# R40 register map
Vendor: Allwinner; Series: R40; File version: 0.1
CPU: CA7 0, little endian, MPU, FPU, double-precision FPU, 0 interrupt priority bits
Registers are 32-bit, read-write, reset 0x0 unless marked. A register's access mark holds for its fields unless they carry their own. Offsets are from the block's base; [hi:lo] are bit positions; lines under a group give offsets from that group; {n}, {i} and the like mark numbered series.

## Thermal_Sensor
Base 0x01C24C00
0x00 THS_CTRL_REG0
  [15:0] SENSOR_ACQ — Sensor acquire time CLK_IN/(N+1)
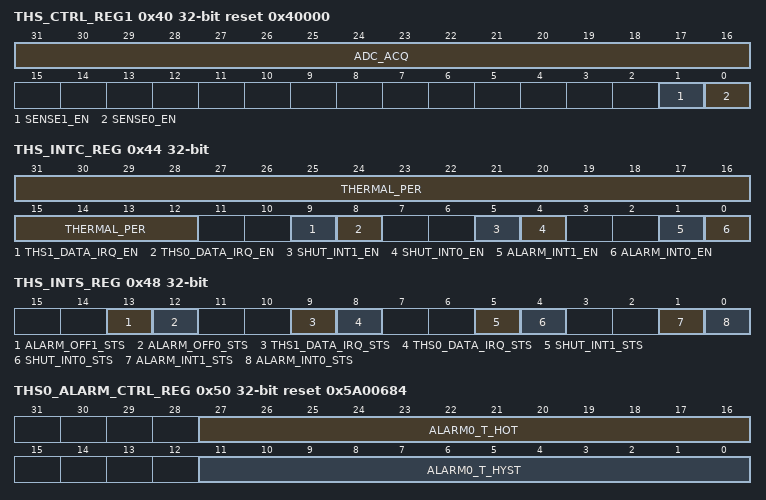
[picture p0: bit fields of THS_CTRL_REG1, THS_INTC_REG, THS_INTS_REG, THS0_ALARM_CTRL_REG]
0x40 THS_CTRL_REG1 reset 0x40000
  [31:16] ADC_ACQ — ADC acquire time CLK_IN/(N+1)
  [1] SENSE1_EN — Enable temperature measurement sensor1 0:Disable 1:Enable
  [0] SENSE0_EN — Enable temperature measurement sensor0 0:Disable 1:Enable
0x44 THS_INTC_REG
  [31:12] THERMAL_PER — 4096*(n+1)/CLK_IN
  [9] THS1_DATA_IRQ_EN — Selects temperature measurement data of sensor1 0: No select 1: Select
    0=No_select; 1=Select
  [8] THS0_DATA_IRQ_EN — Selects temperature measurement data of sensor0 0: No select 1: Select
    0=No_select; 1=Select
  [5] SHUT_INT1_EN — Selects shutdown interrupt for sensor1 0: No select 1: Select
    0=No_select; 1=Select
  [4] SHUT_INT0_EN — Selects shutdown interrupt for sensor0 0: No select 1: Select
    0=No_select; 1=Select
  [1] ALARM_INT1_EN — Selects alarm interrupt for sensor1 0: No select 1: Select
    0=No_select; 1=Select
  [0] ALARM_INT0_EN — Selects alarm interrupt for sensor0 0: No select 1: Select
    0=No_select; 1=Select
0x48 THS_INTS_REG
  [13] ALARM_OFF1_STS write-1-clears — Alarm interrupt off pending for sensor1 Write `1` to clear this interrupt or automatically clear if interrupt condition fails.
  [12] ALARM_OFF0_STS write-1-clears — Alarm interrupt off pending for sensor0 Write `1` to clear this interrupt or automatically clear if interrupt condition fails.
  [9] THS1_DATA_IRQ_STS write-1-clears — Data interrupt status for sensor1 Write `1` to clear this interrupt or automatically clear if interrupt condition fails.
  [8] THS0_DATA_IRQ_STS write-1-clears — Data interrupt status for sensor0 Write `1` to clear this interrupt or automatically clear if interrupt condition fails.
  [5] SHUT_INT1_STS write-1-clears — Shutdown interrupt status for sensor1 Write `1` to clear this interrupt or automatically clear if interrupt condition fails.
  [4] SHUT_INT0_STS write-1-clears — Shutdown interrupt status for sensor0 Write `1` to clear this interrupt or automatically clear if interrupt condition fails.
  [1] ALARM_INT1_STS write-1-clears — Alarm interrupt pending for sensor1 Write `1` to clear this interrupt or automatically clear if interrupt condition fails.
  [0] ALARM_INT0_STS write-1-clears — Alarm interrupt pending for sensor0 Write `1` to clear this interrupt or automatically clear if interrupt condition fails.
0x50 THS0_ALARM_CTRL_REG reset 0x5A00684
  [27:16] ALARM0_T_HOT — Thermal sensor0 alarm threshold for hot temperature
  [11:0] ALARM0_T_HYST — Thermal sensor0 alarm threshold for hysteresis temperature
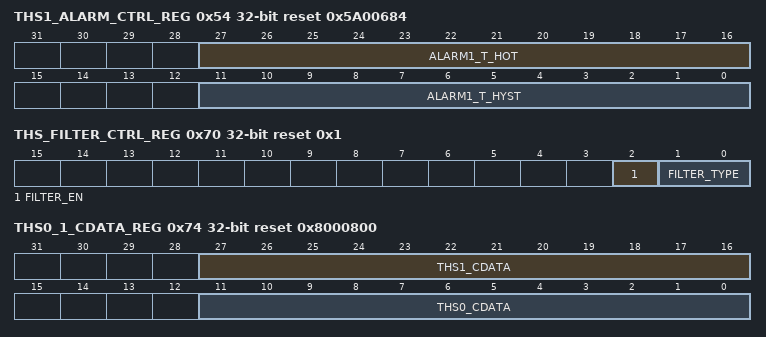
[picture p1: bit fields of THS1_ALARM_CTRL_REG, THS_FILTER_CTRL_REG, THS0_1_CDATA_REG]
0x54 THS1_ALARM_CTRL_REG reset 0x5A00684
  [27:16] ALARM1_T_HOT — Thermal sensor1 alarm threshold for hot temperature
  [11:0] ALARM1_T_HYST — Thermal sensor1 alarm threshold for hysteresis temperature
0x60 THS0_SHUTDOWN_CTRL_REG reset 0x4E90000
  [27:16] SHUT0_T_HOT — Thermal sensor0 shutdown threshold for hot temperature
0x64 THS1_SHUTDOWN_CTRL_REG reset 0x4E90000
  [27:16] SHUT1_T_HOT — Thermal sensor1 shutdown threshold for hot temperature
0x70 THS_FILTER_CTRL_REG reset 0x1
  [2] FILTER_EN — Filter Enable 0: Disable 1: Enable
    0=Disable; 1=Enable
  [1:0] FILTER_TYPE — Average Filter Type 00: 2 01: 4 10: 8 11: 16
    0=_2; 1=_4; 2=_8; 3=_16
0x74 THS0_1_CDATA_REG reset 0x8000800
  [27:16] THS1_CDATA — Thermal Sensor1 calibration data
  [11:0] THS0_CDATA — Thermal Sensor0 calibration data
0x80 THS0_DATA_REG
  [11:0] THS0_DATA ro — Temperature measurement data of sensor0
0x84 THS1_DATA_REG
  [11:0] THS1_DATA ro — Temperature measurement data of sensor1

## TVD_TOP
Base 0x01C30000
0x00 TVD_TOP_MAP
  [1:0] TVD_ADC_MAP — 00: NO MAP 01: 4 CVBS 10: 1 YPbPr and 1 CVBS 11: Reserved
    0=NO_MAP; 1=4 CVBS; 2=1 YPbPr and 1 CVBS
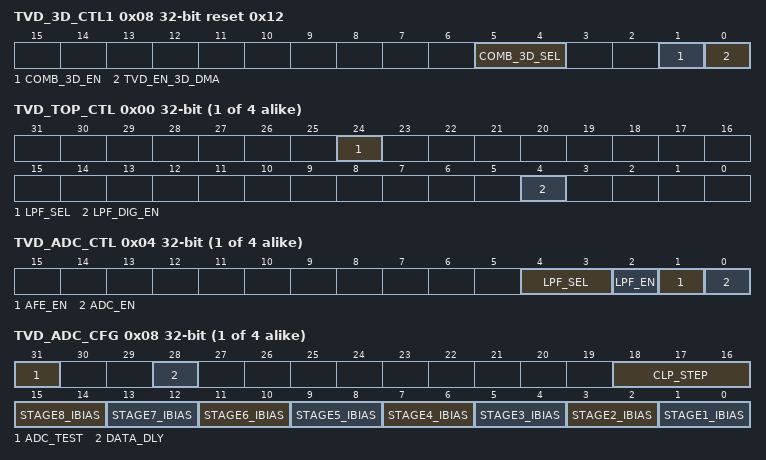
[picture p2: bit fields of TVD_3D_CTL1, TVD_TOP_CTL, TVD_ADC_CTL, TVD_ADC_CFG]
0x08 TVD_3D_CTL1 reset 0x12 — TVD 3D DMA Control Register1
  [5:4] COMB_3D_SEL — 00: TVD0 01: TVD1 10: TVD2 11: TVD3
    {v}=TVD{v} (v=0..3)
  [1] COMB_3D_EN — 0: Disable 1: Enable
    0=Disable; 1=Enable
  [0] TVD_EN_3D_DMA — 0: Disable 1: Enable Set 0x1 when enable 3D comb filter.
    0=Disable; 1=Enable Set 0x1 when enable 3D comb filter
0x0C TVD_3D_CTL2 — TVD 3D DMA Control Register2
  [31:0] DRAM_TRIG
0x10 TVD_3D_CTL3 — TVD 3D DMA Control Register3
  [31:0] COMB_3D_ADDR0
0x14 TVD_3D_CTL4 — TVD 3D DMA Control Register4
  [31:0] COMB_3D_ADDR1
0x18 TVD_3D_CTL5 — TVD 3D DMA Control Register5
  [31:0] COMB_3D_SIZE
{0x24+0x20*i} _N[{i}] (i=0..3) group
  0x00 TVD_TOP_CTL
    [24] LPF_SEL — 0: 6M 1: 8M
      0=_6M; 1=_8M
    [4] LPF_DIG_EN — 0: Disable 1: Enable
      0=Disable; 1=Enable
  0x04 TVD_ADC_CTL — TVD ADC Control Register
    [4:3] LPF_SEL — 0: 11M 1: 16M
    [2] LPF_EN — 0: Disable LPF circuit 1: Enable LPF circuit
      0=Disable LPF circuit; 1=Enable LPF circuit
    [1] AFE_EN — 0: Disable AFE circuit 1: Enable AFE circuit
      0=Disable AFE circuit; 1=Enable AFE circuit
    [0] ADC_EN — 0: Disable ADC circuit 1: Enable ADC circuit
      0=Disable ADC circuit; 1=Enable ADC circuit
  0x08 TVD_ADC_CFG — TVD ADC Configuration Register
    [31] ADC_TEST — adc_test signal en_adctest=1 adc test for ch1
    [28] DATA_DLY — 0: no delay 1: delay ADC output data for half circle for ch1
      0=no_delay; 1=delay ADC output data for half circle for ch1
    [18:16] CLP_STEP — up/dn step size of dc_level
    [2n-1:2n-2] STAGE{n}_IBIAS (n=1..8)

## TVE_TOP
Base 0x01C90000
{0x20+0x20*i} _N[{i}] (i=0..3) group
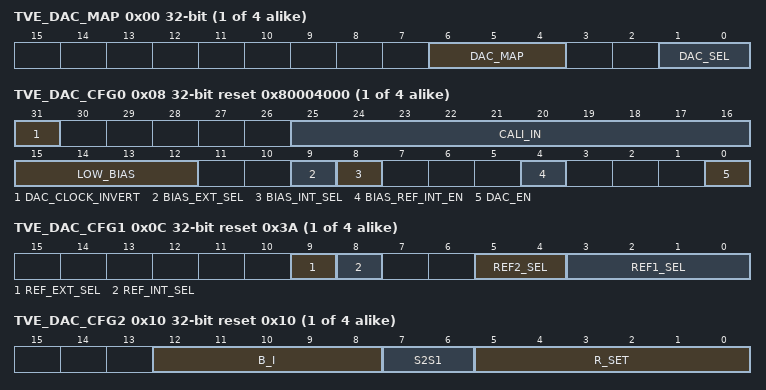
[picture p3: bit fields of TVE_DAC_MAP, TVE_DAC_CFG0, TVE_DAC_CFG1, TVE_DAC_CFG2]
  0x00 TVE_DAC_MAP — TV Encoder DAC MAP Register
    [6:4] DAC_MAP — 000: OUT0 001: OUT1 010: OUT2 011: OUT3 Others: Reserved
      0=OUT0; 1=OUT1; 2=OUT2; 3=OUT3 (OUT3 Others: Reserved)
    [1:0] DAC_SEL — 00: NO 01: TVE0 10: TVE1 11: Reserved
      0=NO; 1=TVE0; 2=TVE1
  0x04 TVE_DAC_STATUS — TV Encoder DAC STAUTS Register
    [1:0] DAC_STATUS — 00: Unconnected 01: Connected 11: Short to ground 10: Reserved
      0=Unconnected; 1=Connected; 3=Short to ground
  0x08 TVE_DAC_CFG0 reset 0x80004000 — TV Encoder DAC CFG0 Register
    [31] DAC_CLOCK_INVERT — 0: Not invert 1: Invert
      0=Not_invert; 1=Invert
    [25:16] CALI_IN
    [15:12] LOW_BIAS — 500uA to 4mA
    [9] BIAS_EXT_SEL — 0: Disable 1: Enable (a_sel_bias_adda)
      0=Disable; 1=Enable (a_sel_bias_adda)
    [8] BIAS_INT_SEL — 0: Disable 1: Enable (a_sel_bias_res)
      0=Disable; 1=Enable (a_sel_bias_res)
    [4] BIAS_REF_INT_EN — 0: Disable 1: Enable (a_en_resref)
      0=Disable; 1=Enable (a_en_resref)
    [0] DAC_EN — 0: Disable 1: Enable
      0=Disable; 1=Enable
  0x0C TVE_DAC_CFG1 reset 0x3A — TV Encoder DAC CFG1 Register
    [9] REF_EXT_SEL — 0: Disable 1: Enable (a_sel_detref_ldo)
      0=Disable; 1=Enable (a_sel_detref_ldo)
    [8] REF_INT_SEL — 0: Disable 1: Enable (a_sel_detref_res)
      0=Disable; 1=Enable (a_sel_detref_res)
    [5:4] REF2_SEL — 00: 0.25V 01: 0.30V 10: 0.35V 11: 0.40V (a_refslct2<1:0>)
      0=_0_point_25V (0.25V); 1=_0_point_30V (0.30V); 2=_0_point_35V (0.35V); 3=_0_point_40V (0.40V (a_refslct2<1:0>))
    [3:0] REF1_SEL — 0000: 0.50V 0001: 0.55V 0010: 0.60V 0011: 0.65V 0100: 0.70V 0101: 0.75V 0110: 0.80V 0111: 0.85V 1000: 0.90V 1001: 0.95V 1010: 1.00V 1011: 1.05V 1100: 1.10V 1101: 1.15V 1110: 1.20V 1111: 1.25V (a_refslct1<3:0>)
      0=_0_point_50V (0.50V); 1=_0_point_55V (0.55V); 2=_0_point_60V (0.60V); 3=_0_point_65V (0.65V); 4=_0_point_70V (0.70V); 5=_0_point_75V (0.75V); 6=_0_point_80V (0.80V); 7=_0_point_85V (0.85V); 8=_0_point_90V (0.90V); 9=_0_point_95V (0.95V); 10=_1_point_00V (1.00V); 11=_1_point_05V (1.05V); 12=_1_point_10V (1.10V); 13=_1_point_15V (1.15V); 14=_1_point_20V (1.20V); 15=_1_point_25V (1.25V (a_refslct1<3:0>))
  0x10 TVE_DAC_CFG2 reset 0x10 — TV Encoder DAC CFG2 Register
    [12:8] B_I — B ( I config output current for different peak voltage)
    [7:6] S2S1
    [5:0] R_SET
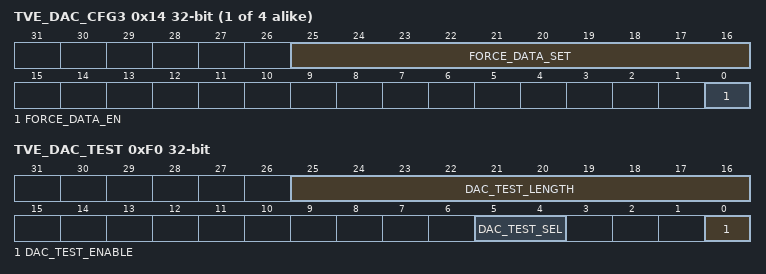
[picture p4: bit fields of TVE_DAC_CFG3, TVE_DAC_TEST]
  0x14 TVE_DAC_CFG3 — TV Encoder DAC CFG2 Register
    [25:16] FORCE_DATA_SET — Force DAC input data
    [0] FORCE_DATA_EN — 0:DAC input data from TVE 1: DAC input data from FORCE_DATA_SET
      1=DAC (DAC input data from FORCE_DATA_SET)
0xF0 TVE_DAC_TEST — TV Encoder DAC TEST Register
  [25:16] DAC_TEST_LENGTH — DAC TEST DATA LENGTH
  [5:4] DAC_TEST_SEL — 00: DAC0 01: DAC1 10: DAC2 11: DAC3
    {v}=DAC{v} (v=0..3)
  [0] DAC_TEST_ENABLE — 0: Reserved 1: Repeat DAC data from DAC sram
    1=Repeat DAC data from DAC sram
